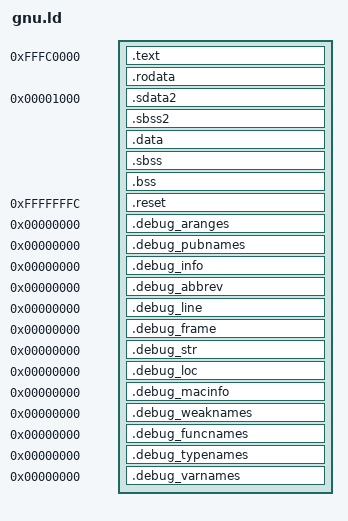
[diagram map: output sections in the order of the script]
OUTPUT_FORMAT("elf32-powerpc", "elf32-powerpc",
              "elf32-powerpc")
OUTPUT_ARCH(powerpc:common)
ENTRY(_start)
SECTIONS
{
  /* Read-only sections, merged into text segment: */
  . = 0xfffc0000;
  .text           :
  {
    *(.text .text.* .gnu.linkonce.t.*)
    /* .gnu.warning sections are handled specially by elf32.em.  */
    *(.gnu.warning)
    __text_end = .;
  } = 0
  .rodata :
  {
    *(.rodata .rodata.* .gnu.linkonce.r.*)
    *(.rodata1)
    . = ALIGN(4);
    __rodata_end = .;
  } =0
  . = 0x1000;
  __sdata2_load = __rodata_end;
  .sdata2 : AT (__sdata2_load)
  {
    __sdata2_start = .;
    PROVIDE (_SDA2_BASE_ = 32768);
    *(.sdata2 .sdata2.* .gnu.linkonce.s2.*)
    . = ALIGN(4);
    __sdata2_end = .;
  }
  .sbss2 :
  {
    __sbss2_start = .;
    *(.sbss2 .sbss2.* .gnu.linkonce.sb2.*)
    . = ALIGN(4);
    __sbss2_end = .;
  }
  __data_load = __sdata2_load + SIZEOF (.sdata2);
  .data : AT(__data_load)
  {
    __data_start = .;
    *(.data .data.* .gnu.linkonce.d.*)
    KEEP (*(.gnu.linkonce.d.*personality*))
    SORT(CONSTRUCTORS)
    *(.data1)
    PROVIDE (_SDA_BASE_ = 32768);
    *(.sdata .sdata.* .gnu.linkonce.s.*)
    . = ALIGN(4);
    __data_end = .;
  }
  .sbss :
  {
    __sbss_start = .;
    *(.dynsbss)
    *(.sbss .sbss.* .gnu.linkonce.sb.*)
    *(.scommon)
    __sbss_end = .;
  }
  .bss  :
  {
   __bss_start = .;
   *(.dynbss)
   *(.bss .bss.* .gnu.linkonce.b.*)
   *(COMMON)
   . = ALIGN(4);
   __bss_end = .;

   /* Allocate the main stack area.  Make sure it starts 16bytes aligned
      to accommodate any possible program expectation.  */
   _stack = ALIGN(16) + 0x1000;
   _end = _stack;
  }

  . = 0xfffffffc;
  .reset : AT (0xfffffffc)
  {
   KEEP(*(.reset))
  }

  /* DWARF 1.1 and DWARF 2 */
  .debug_aranges  0 : { *(.debug_aranges) }
  .debug_pubnames 0 : { *(.debug_pubnames) }
  /* DWARF 2 */
  .debug_info     0 : { *(.debug_info .gnu.linkonce.wi.*) }
  .debug_abbrev   0 : { *(.debug_abbrev) }
  .debug_line     0 : { *(.debug_line) }
  .debug_frame    0 : { *(.debug_frame) }
  .debug_str      0 : { *(.debug_str) }
  .debug_loc      0 : { *(.debug_loc) }
  .debug_macinfo  0 : { *(.debug_macinfo) }
  /* SGI/MIPS DWARF 2 extensions */
  .debug_weaknames 0 : { *(.debug_weaknames) }
  .debug_funcnames 0 : { *(.debug_funcnames) }
  .debug_typenames 0 : { *(.debug_typenames) }
  .debug_varnames  0 : { *(.debug_varnames) }
  /DISCARD/ : { *(.note.GNU-stack) }
}

